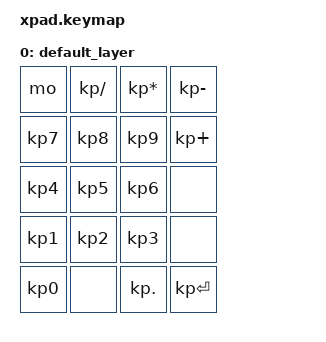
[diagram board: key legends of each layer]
#include <behaviors.dtsi>
#include <dt-bindings/zmk/keys.h>

/ {
    keymap {
        compatible = "zmk,keymap";

        default_layer {
// --------------------------------------------------------------------------------------------------------------------------------------------------------------------
// |   MO(1) |    /    |    *    |    -    |
// |    7    |    8    |    9    |    +    |
// |    4    |    5    |    6    |   none  |
// |    1    |    2    |    3    |   none  |
// |    0    |   none  |    .    |   enter |

            bindings = <
    &kp mo 1    &kp KP_DIVIDE    &kp KP_MULTIPLY    &kp KP_MINUS
    &kp KP_N7    &kp KP_N8    &kp KP_N9    &kp KP_PLUS
    &kp KP_N4    &kp KP_N5    &kp KP_N6    &none
    &kp KP_N1    &kp KP_N2    &kp KP_N3    &none
    &kp KP_N0    &none    &kp KP_DOT    &kp KP_ENTER
            >;

        };
    };
};
